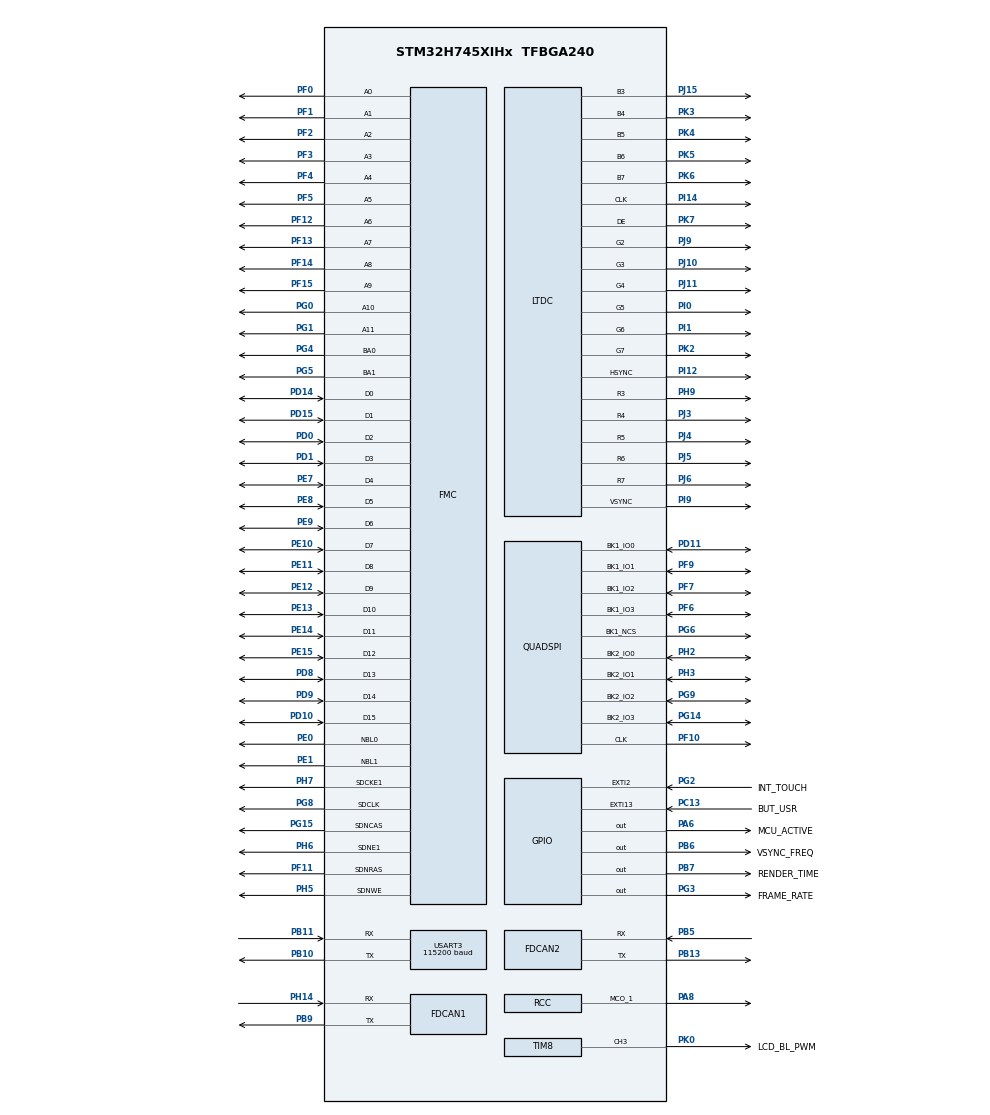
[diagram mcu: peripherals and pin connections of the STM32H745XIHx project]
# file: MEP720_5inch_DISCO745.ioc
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CORTEX_M7.AccessPermission-Cortex_Memory_Protection_Unit_Region0_Settings=MPU_REGION_FULL_ACCESS
CORTEX_M7.AccessPermission-Cortex_Memory_Protection_Unit_Region1_Settings=MPU_REGION_FULL_ACCESS
CORTEX_M7.AccessPermission-Cortex_Memory_Protection_Unit_Region2_Settings=MPU_REGION_FULL_ACCESS
CORTEX_M7.BaseAddress-Cortex_Memory_Protection_Unit_Region0_Settings=0x24000000
CORTEX_M7.BaseAddress-Cortex_Memory_Protection_Unit_Region1_Settings=0xD0000000
CORTEX_M7.BaseAddress-Cortex_Memory_Protection_Unit_Region2_Settings=0x90000000
CORTEX_M7.CPU_DCache=Enabled
CORTEX_M7.CPU_ICache=Enabled
CORTEX_M7.DisableExec-Cortex_Memory_Protection_Unit_Region0_Settings=MPU_INSTRUCTION_ACCESS_DISABLE
CORTEX_M7.DisableExec-Cortex_Memory_Protection_Unit_Region1_Settings=MPU_INSTRUCTION_ACCESS_ENABLE
CORTEX_M7.DisableExec-Cortex_Memory_Protection_Unit_Region2_Settings=MPU_INSTRUCTION_ACCESS_DISABLE
CORTEX_M7.Enable-Cortex_Memory_Protection_Unit_Region0_Settings=MPU_REGION_ENABLE
CORTEX_M7.Enable-Cortex_Memory_Protection_Unit_Region1_Settings=MPU_REGION_ENABLE
CORTEX_M7.Enable-Cortex_Memory_Protection_Unit_Region2_Settings=MPU_REGION_ENABLE
CORTEX_M7.Enable-Cortex_Memory_Protection_Unit_Region3_Settings=__NULL
CORTEX_M7.Enable-Cortex_Memory_Protection_Unit_Region4_Settings=__NULL
CORTEX_M7.IsBufferable-Cortex_Memory_Protection_Unit_Region0_Settings=MPU_ACCESS_BUFFERABLE
CORTEX_M7.IsBufferable-Cortex_Memory_Protection_Unit_Region1_Settings=MPU_ACCESS_NOT_BUFFERABLE
CORTEX_M7.IsBufferable-Cortex_Memory_Protection_Unit_Region2_Settings=MPU_ACCESS_BUFFERABLE
CORTEX_M7.IsCacheable-Cortex_Memory_Protection_Unit_Region0_Settings=MPU_ACCESS_CACHEABLE
CORTEX_M7.IsCacheable-Cortex_Memory_Protection_Unit_Region1_Settings=MPU_ACCESS_CACHEABLE
CORTEX_M7.IsCacheable-Cortex_Memory_Protection_Unit_Region2_Settings=MPU_ACCESS_CACHEABLE
CORTEX_M7.IsShareable-Cortex_Memory_Protection_Unit_Region1_Settings=MPU_ACCESS_NOT_SHAREABLE
CORTEX_M7.MPU_Control=MPU_PRIVILEGED_DEFAULT
CORTEX_M7.Size-Cortex_Memory_Protection_Unit_Region0_Settings=MPU_REGION_SIZE_512KB
CORTEX_M7.Size-Cortex_Memory_Protection_Unit_Region1_Settings=MPU_REGION_SIZE_8MB
CORTEX_M7.Size-Cortex_Memory_Protection_Unit_Region2_Settings=MPU_REGION_SIZE_128MB
CORTEX_M7.SubRegionDisable-Cortex_Memory_Protection_Unit_Region0_Settings=0x87
CortexM4.IPs=CORTEX_M4\:I,DEBUG,FATFS_M4\:I,FREERTOS_M4\:I,IWDG2\:I,OPENAMP_M4\:I,PDM2PCM_M4\:I,PWR,RCC,RESMGR_UTILITY,SYS_M4\:I,USB_DEVICE_M4\:I,USB_HOST_M4\:I,VREFBUF,WWDG2\:I,DMA,BDMA,MDMA,NVIC2\:I,GPIO,LPTIM3\:I
CortexM7.IPs=CORTEX_M7\:I,DEBUG\:I,FATFS_M7\:I,FREERTOS_M7\:I,IWDG1\:I,OPENAMP_M7\:I,PDM2PCM_M7\:I,PWR\:I,RCC\:I,RESMGR_UTILITY\:I,SYS\:I,USB_DEVICE_M7\:I,USB_HOST_M7\:I,VREFBUF\:I,WWDG1\:I,DMA\:I,BDMA\:I,MDMA\:I,NVIC1\:I,TIM6\:I,CRC\:I,LTDC\:I,DMA2D\:I,FMC\:I,QUADSPI\:I,GPIO\:I,JPEG\:I,FDCAN1\:I,FDCAN2\:I,USART3\:I,MEMORYMAP\:I,TIM8\:I,RTC\:I
CortexM7.Pins=PB6,PB7,PC13,PG3,PG2,PA6
DMA2D.ColorMode=DMA2D_OUTPUT_RGB565
DMA2D.Mode=DMA2D_R2M
FDCAN1.CalculateBaudRateNominal=1666666
FDCAN1.CalculateTimeBitNominal=600
FDCAN1.CalculateTimeQuantumNominal=200.0
FDCAN2.CalculateBaudRateNominal=1666666
FDCAN2.CalculateTimeBitNominal=600
FDCAN2.CalculateTimeQuantumNominal=200.0
FMC.CASLatency2=FMC_SDRAM_CAS_LATENCY_2
FMC.ExitSelfRefreshDelay2=6
FMC.LoadToActiveDelay2=2
FMC.RCDDelay2=2
FMC.RPDelay1=2
FMC.RPDelay2=2
FMC.ReadBurst2=FMC_SDRAM_RBURST_ENABLE
FMC.RowCycleDelay1=6
FMC.RowCycleDelay2=6
FMC.SDClockPeriod2=FMC_SDRAM_CLOCK_PERIOD_2
FMC.SelfRefreshTime2=4
FMC.WriteRecoveryTime2=2
FREERTOS_M7.Tasks01=defaultTask,8,1024,StartDefaultTask,Default,NULL,Static,defaultTaskBuffer,defaultTaskControlBlock
FREERTOS_M7.configGENERATE_RUN_TIME_STATS=1
FREERTOS_M7.configIDLE_SHOULD_YIELD=0
FREERTOS_M7.configMINIMAL_STACK_SIZE=512
FREERTOS_M7.configRECORD_STACK_HIGH_ADDRESS=1
FREERTOS_M7.configTIMER_TASK_PRIORITY=50
FREERTOS_M7.configTOTAL_HEAP_SIZE=65535
FREERTOS_M7.configUSE_NEWLIB_REENTRANT=1
FREERTOS_M7.configUSE_STATS_FORMATTING_FUNCTIONS=1
JPEG.JPEG_RGB_FORMAT=JPEG_RGB565
JPEG.USE_JPEG_ENCODER=0
LTDC.ActiveH=480
LTDC.ActiveW=800
LTDC.Alpha0_L0=0
LTDC.Alpha_L0=255
LTDC.BlendingFactor1_L0=LTDC_BLENDING_FACTOR1_CA
LTDC.BlendingFactor2_L0=LTDC_BLENDING_FACTOR2_CA
LTDC.FBStartAdress_L0=ltdc_buffer_addr()
LTDC.HBP=8
LTDC.HFP=8
LTDC.HSync=4
LTDC.ImageHeight_L0=480
LTDC.ImageWidth_L0=800
LTDC.Layers=0
LTDC.PixelFormat_L0=LTDC_PIXEL_FORMAT_RGB565
LTDC.VBP=8
LTDC.VFP=8
LTDC.VSync=4
LTDC.WindowX1_L0=800
LTDC.WindowY1_L0=480
Mcu.Family=STM32H7
Mcu.Name=STM32H745XIHx
Mcu.Package=TFBGA240
Mdma.MDMA_Channel6.JPEG_OUTFIFO_TH.0.BlockCount=0
Mdma.MDMA_Channel6.JPEG_OUTFIFO_TH.0.BlockDataLength=0
Mdma.MDMA_Channel6.JPEG_OUTFIFO_TH.0.BufferTransferLength=32
Mdma.MDMA_Channel6.JPEG_OUTFIFO_TH.0.CircularMode=MDMA_LINEAR_LIST
Mdma.MDMA_Channel6.JPEG_OUTFIFO_TH.0.DataAlignment=MDMA_DATAALIGN_PACKENABLE
Mdma.MDMA_Channel6.JPEG_OUTFIFO_TH.0.DestBlockAddressOffset=0
Mdma.MDMA_Channel6.JPEG_OUTFIFO_TH.0.DestBurst=MDMA_DEST_BURST_32BEATS
Mdma.MDMA_Channel6.JPEG_OUTFIFO_TH.0.DestDataSize=MDMA_DEST_DATASIZE_BYTE
Mdma.MDMA_Channel6.JPEG_OUTFIFO_TH.0.DestinationInc=MDMA_DEST_INC_BYTE
Mdma.MDMA_Channel6.JPEG_OUTFIFO_TH.0.DstAddress=0
Mdma.MDMA_Channel6.JPEG_OUTFIFO_TH.0.Endianness=MDMA_LITTLE_ENDIANNESS_PRESERVE
Mdma.MDMA_Channel6.JPEG_OUTFIFO_TH.0.Instance=MDMA_Channel6
Mdma.MDMA_Channel6.JPEG_OUTFIFO_TH.0.MaskAddress=0
Mdma.MDMA_Channel6.JPEG_OUTFIFO_TH.0.MaskData=0
Mdma.MDMA_Channel6.JPEG_OUTFIFO_TH.0.Priority=MDMA_PRIORITY_VERY_HIGH
Mdma.MDMA_Channel6.JPEG_OUTFIFO_TH.0.Rank=First
Mdma.MDMA_Channel6.JPEG_OUTFIFO_TH.0.SourceBlockAddressOffset=0
Mdma.MDMA_Channel6.JPEG_OUTFIFO_TH.0.SourceBurst=MDMA_SOURCE_BURST_32BEATS
Mdma.MDMA_Channel6.JPEG_OUTFIFO_TH.0.SourceDataSize=MDMA_SRC_DATASIZE_WORD
Mdma.MDMA_Channel6.JPEG_OUTFIFO_TH.0.SourceInc=MDMA_SRC_INC_DISABLE
Mdma.MDMA_Channel6.JPEG_OUTFIFO_TH.0.SrcAddress=0
Mdma.MDMA_Channel6.JPEG_OUTFIFO_TH.0.TransferTriggerMode=MDMA_BUFFER_TRANSFER
Mdma.MDMA_Channel6.Request0=JPEG_OUTFIFO_TH
Mdma.MDMA_Channel6.RequestsNb=1
Mdma.MDMA_Channel7.JPEG_INFIFO_TH.0.BlockCount=0
Mdma.MDMA_Channel7.JPEG_INFIFO_TH.0.BlockDataLength=0
Mdma.MDMA_Channel7.JPEG_INFIFO_TH.0.BufferTransferLength=32
Mdma.MDMA_Channel7.JPEG_INFIFO_TH.0.CircularMode=MDMA_LINEAR_LIST
Mdma.MDMA_Channel7.JPEG_INFIFO_TH.0.DataAlignment=MDMA_DATAALIGN_PACKENABLE
Mdma.MDMA_Channel7.JPEG_INFIFO_TH.0.DestBlockAddressOffset=0
Mdma.MDMA_Channel7.JPEG_INFIFO_TH.0.DestBurst=MDMA_DEST_BURST_16BEATS
Mdma.MDMA_Channel7.JPEG_INFIFO_TH.0.DestDataSize=MDMA_DEST_DATASIZE_WORD
Mdma.MDMA_Channel7.JPEG_INFIFO_TH.0.DestinationInc=MDMA_DEST_INC_DISABLE
Mdma.MDMA_Channel7.JPEG_INFIFO_TH.0.DstAddress=0
Mdma.MDMA_Channel7.JPEG_INFIFO_TH.0.Endianness=MDMA_LITTLE_ENDIANNESS_PRESERVE
Mdma.MDMA_Channel7.JPEG_INFIFO_TH.0.Instance=MDMA_Channel7
Mdma.MDMA_Channel7.JPEG_INFIFO_TH.0.MaskAddress=0
Mdma.MDMA_Channel7.JPEG_INFIFO_TH.0.MaskData=0
Mdma.MDMA_Channel7.JPEG_INFIFO_TH.0.Priority=MDMA_PRIORITY_HIGH
Mdma.MDMA_Channel7.JPEG_INFIFO_TH.0.Rank=First
Mdma.MDMA_Channel7.JPEG_INFIFO_TH.0.SourceBlockAddressOffset=0
Mdma.MDMA_Channel7.JPEG_INFIFO_TH.0.SourceBurst=MDMA_SOURCE_BURST_32BEATS
Mdma.MDMA_Channel7.JPEG_INFIFO_TH.0.SourceDataSize=MDMA_SRC_DATASIZE_BYTE
Mdma.MDMA_Channel7.JPEG_INFIFO_TH.0.SourceInc=MDMA_SRC_INC_BYTE
Mdma.MDMA_Channel7.JPEG_INFIFO_TH.0.SrcAddress=0
Mdma.MDMA_Channel7.JPEG_INFIFO_TH.0.TransferTriggerMode=MDMA_BUFFER_TRANSFER
Mdma.MDMA_Channel7.Request0=JPEG_INFIFO_TH
Mdma.MDMA_Channel7.RequestsNb=1
Mdma.RequestSet0=MDMA_Channel7
Mdma.RequestSet1=MDMA_Channel6
Mdma.RequestSetsNb=2
NVIC1.DMA2D_IRQn=true\:5\:0\:false\:false\:true\:true\:true\:true\:true
NVIC1.EXTI15_10_IRQn=true\:5\:0\:false\:false\:true\:true\:true\:true\:true
NVIC1.EXTI2_IRQn=true\:5\:0\:false\:false\:true\:true\:true\:true\:true
NVIC1.FDCAN1_IT0_IRQn=true\:5\:0\:false\:false\:true\:true\:true\:true\:true
NVIC1.FDCAN2_IT0_IRQn=true\:5\:0\:false\:false\:true\:true\:true\:true\:true
NVIC1.JPEG_IRQn=true\:5\:0\:true\:false\:true\:true\:true\:true\:true
NVIC1.LTDC_IRQn=true\:5\:0\:false\:false\:true\:true\:true\:true\:true
NVIC1.MDMA_IRQn=true\:5\:0\:true\:false\:true\:true\:false\:true\:true
NVIC1.PriorityGroup=NVIC_PRIORITYGROUP_4
NVIC1.QUADSPI_IRQn=true\:5\:0\:false\:false\:true\:true\:true\:true\:true
NVIC1.TIM6_DAC_IRQn=true\:15\:0\:true\:false\:true\:false\:false\:true\:true
NVIC1.TimeBase=TIM6_DAC_IRQn
NVIC1.TimeBaseIP=TIM6
NVIC2.PriorityGroup=NVIC_PRIORITYGROUP_4
PA6.GPIO_Label=MCU_ACTIVE
PA6.GPIO_Speed=GPIO_SPEED_FREQ_VERY_HIGH
PA6.PinAttribute=CortexM7
PA6.Signal=GPIO_Output
PA8.Mode=Clock-out-1
PA8.PinAttribute=Free
PA8.Signal=RCC_MCO_1
PB10.Mode=Asynchronous
PB10.PinAttribute=CortexM7
PB10.Signal=USART3_TX
PB11.GPIO_PuPd=GPIO_PULLUP
PB11.Mode=Asynchronous
PB11.PinAttribute=CortexM7
PB11.Signal=USART3_RX
PB13.Mode=FDCAN_Activate
PB13.PinAttribute=CortexM7
PB13.Signal=FDCAN2_TX
PB5.Mode=FDCAN_Activate
PB5.PinAttribute=CortexM7
PB5.Signal=FDCAN2_RX
PB6.GPIO_Label=VSYNC_FREQ
PB6.GPIO_Speed=GPIO_SPEED_FREQ_VERY_HIGH
PB6.PinAttribute=CortexM7
PB6.Signal=GPIO_Output
PB7.GPIO_FM7=__NULL
PB7.GPIO_Label=RENDER_TIME
PB7.GPIO_Speed=GPIO_SPEED_FREQ_VERY_HIGH
PB7.PinAttribute=CortexM7
PB7.Signal=GPIO_Output
PB9.Mode=FDCAN_Activate
PB9.PinAttribute=CortexM7
PB9.Signal=FDCAN1_TX
PC13.GPIO_Label=BUT_USR
PC13.GPIO_ModeDefaultEXTI=GPIO_MODE_IT_RISING
PC13.GPIO_PuPd=GPIO_NOPULL
PC13.PinAttribute=CortexM7
PC13.Signal=GPXTI13
PC14-OSC32_IN\ (OSC32_IN).Mode=LSE-External-Oscillator
PC14-OSC32_IN\ (OSC32_IN).PinAttribute=Free
PC14-OSC32_IN\ (OSC32_IN).Signal=RCC_OSC32_IN
PC15-OSC32_OUT\ (OSC32_OUT).Mode=LSE-External-Oscillator
PC15-OSC32_OUT\ (OSC32_OUT).PinAttribute=Free
PC15-OSC32_OUT\ (OSC32_OUT).Signal=RCC_OSC32_OUT
PD0.PinAttribute=CortexM7
PD0.Signal=FMC_D2_DA2
PD1.PinAttribute=CortexM7
PD1.Signal=FMC_D3_DA3
PD10.PinAttribute=CortexM7
PD10.Signal=FMC_D15_DA15
PD11.GPIO_Speed=GPIO_SPEED_FREQ_VERY_HIGH
PD11.Mode=Dual_Bank
PD11.PinAttribute=CortexM7
PD11.Signal=QUADSPI_BK1_IO0
PD14.PinAttribute=CortexM7
PD14.Signal=FMC_D0_DA0
PD15.PinAttribute=CortexM7
PD15.Signal=FMC_D1_DA1
PD8.PinAttribute=CortexM7
PD8.Signal=FMC_D13_DA13
PD9.PinAttribute=CortexM7
PD9.Signal=FMC_D14_DA14
PE0.PinAttribute=CortexM7
PE0.Signal=FMC_NBL0
PE1.PinAttribute=CortexM7
PE1.Signal=FMC_NBL1
PE10.PinAttribute=CortexM7
PE10.Signal=FMC_D7_DA7
PE11.PinAttribute=CortexM7
PE11.Signal=FMC_D8_DA8
PE12.PinAttribute=CortexM7
PE12.Signal=FMC_D9_DA9
PE13.PinAttribute=CortexM7
PE13.Signal=FMC_D10_DA10
PE14.PinAttribute=CortexM7
PE14.Signal=FMC_D11_DA11
PE15.PinAttribute=CortexM7
PE15.Signal=FMC_D12_DA12
PE7.PinAttribute=CortexM7
PE7.Signal=FMC_D4_DA4
PE8.PinAttribute=CortexM7
PE8.Signal=FMC_D5_DA5
PE9.PinAttribute=CortexM7
PE9.Signal=FMC_D6_DA6
PF0.PinAttribute=CortexM7
PF0.Signal=FMC_A0
PF1.PinAttribute=CortexM7
PF1.Signal=FMC_A1
PF10.GPIO_Speed=GPIO_SPEED_FREQ_VERY_HIGH
PF10.Mode=Dual_Bank
PF10.PinAttribute=CortexM7
PF10.Signal=QUADSPI_CLK
PF11.PinAttribute=CortexM7
PF11.Signal=FMC_SDNRAS
PF12.PinAttribute=CortexM7
PF12.Signal=FMC_A6
PF13.PinAttribute=CortexM7
PF13.Signal=FMC_A7
PF14.PinAttribute=CortexM7
PF14.Signal=FMC_A8
PF15.PinAttribute=CortexM7
PF15.Signal=FMC_A9
PF2.PinAttribute=CortexM7
PF2.Signal=FMC_A2
PF3.PinAttribute=CortexM7
PF3.Signal=FMC_A3
PF4.PinAttribute=CortexM7
PF4.Signal=FMC_A4
PF5.PinAttribute=CortexM7
PF5.Signal=FMC_A5
PF6.GPIO_Speed=GPIO_SPEED_FREQ_VERY_HIGH
PF6.Mode=Dual_Bank
PF6.PinAttribute=CortexM7
PF6.Signal=QUADSPI_BK1_IO3
PF7.GPIO_Speed=GPIO_SPEED_FREQ_VERY_HIGH
PF7.Mode=Dual_Bank
PF7.PinAttribute=CortexM7
PF7.Signal=QUADSPI_BK1_IO2
PF9.GPIO_Speed=GPIO_SPEED_FREQ_VERY_HIGH
PF9.Mode=Dual_Bank
PF9.PinAttribute=CortexM7
PF9.Signal=QUADSPI_BK1_IO1
PG0.PinAttribute=CortexM7
PG0.Signal=FMC_A10
PG1.PinAttribute=CortexM7
PG1.Signal=FMC_A11
PG14.GPIO_Speed=GPIO_SPEED_FREQ_VERY_HIGH
PG14.Mode=Dual_Bank
PG14.PinAttribute=CortexM7
PG14.Signal=QUADSPI_BK2_IO3
PG15.PinAttribute=CortexM7
PG15.Signal=FMC_SDNCAS
PG2.GPIO_Label=INT_TOUCH
PG2.GPIO_ModeDefaultEXTI=GPIO_MODE_IT_FALLING
PG2.GPIO_PuPd=GPIO_PULLUP
PG2.PinAttribute=CortexM7
PG2.Signal=GPXTI2
PG3.GPIO_Label=FRAME_RATE
PG3.GPIO_Speed=GPIO_SPEED_FREQ_VERY_HIGH
PG3.PinAttribute=CortexM7
PG3.Signal=GPIO_Output
PG4.PinAttribute=CortexM7
PG4.Signal=FMC_A14_BA0
PG5.PinAttribute=CortexM7
PG5.Signal=FMC_A15_BA1
PG6.GPIO_PuPd=GPIO_PULLUP
PG6.GPIO_Speed=GPIO_SPEED_FREQ_VERY_HIGH
PG6.Mode=Enable Chip Select 1 for both banks
PG6.PinAttribute=CortexM7
PG6.Signal=QUADSPI_BK1_NCS
PG8.PinAttribute=CortexM7
PG8.Signal=FMC_SDCLK
PG9.GPIO_Speed=GPIO_SPEED_FREQ_VERY_HIGH
PG9.Mode=Dual_Bank
PG9.PinAttribute=CortexM7
PG9.Signal=QUADSPI_BK2_IO2
PH0-OSC_IN\ (PH0).Mode=HSE-External-Oscillator
PH0-OSC_IN\ (PH0).PinAttribute=Free
PH0-OSC_IN\ (PH0).Signal=RCC_OSC_IN
PH1-OSC_OUT\ (PH1).Mode=HSE-External-Oscillator
PH1-OSC_OUT\ (PH1).PinAttribute=Free
PH1-OSC_OUT\ (PH1).Signal=RCC_OSC_OUT
PH14.Mode=FDCAN_Activate
PH14.PinAttribute=CortexM7
PH14.Signal=FDCAN1_RX
PH2.GPIO_Speed=GPIO_SPEED_FREQ_VERY_HIGH
PH2.Mode=Dual_Bank
PH2.PinAttribute=CortexM7
PH2.Signal=QUADSPI_BK2_IO0
PH3.GPIO_Speed=GPIO_SPEED_FREQ_VERY_HIGH
PH3.Mode=Dual_Bank
PH3.PinAttribute=CortexM7
PH3.Signal=QUADSPI_BK2_IO1
PH5.PinAttribute=CortexM7
PH5.Signal=FMC_SDNWE
PH6.Mode=SdramChipSelect2_2
PH6.PinAttribute=CortexM7
PH6.Signal=FMC_SDNE1
PH7.Mode=SdramChipSelect2_2
PH7.PinAttribute=CortexM7
PH7.Signal=FMC_SDCKE1
PH9.GPIO_Speed=GPIO_SPEED_FREQ_HIGH
PH9.Mode=RGB565
PH9.PinAttribute=CortexM7
PH9.Signal=LTDC_R3
PI0.GPIO_Speed=GPIO_SPEED_FREQ_HIGH
PI0.Mode=RGB565
PI0.PinAttribute=CortexM7
PI0.Signal=LTDC_G5
PI1.GPIO_Speed=GPIO_SPEED_FREQ_HIGH
PI1.Mode=RGB565
PI1.PinAttribute=CortexM7
PI1.Signal=LTDC_G6
PI12.GPIO_Speed=GPIO_SPEED_FREQ_HIGH
PI12.Mode=RGB565
PI12.PinAttribute=CortexM7
PI12.Signal=LTDC_HSYNC
PI14.GPIO_Speed=GPIO_SPEED_FREQ_HIGH
PI14.Mode=RGB565
PI14.PinAttribute=CortexM7
PI14.Signal=LTDC_CLK
PI15.GPIO_Speed=GPIO_SPEED_FREQ_HIGH
PI15.PinAttribute=CortexM7
PI15.Signal=LTDC_R0
PI9.GPIO_Speed=GPIO_SPEED_FREQ_HIGH
PI9.Mode=RGB565
PI9.PinAttribute=CortexM7
PI9.Signal=LTDC_VSYNC
PJ0.GPIO_Speed=GPIO_SPEED_FREQ_HIGH
PJ0.PinAttribute=CortexM7
PJ0.Signal=LTDC_R1
PJ1.GPIO_Speed=GPIO_SPEED_FREQ_HIGH
PJ1.PinAttribute=CortexM7
PJ1.Signal=LTDC_R2
PJ10.GPIO_Speed=GPIO_SPEED_FREQ_HIGH
PJ10.Mode=RGB565
PJ10.PinAttribute=CortexM7
PJ10.Signal=LTDC_G3
PJ11.GPIO_Speed=GPIO_SPEED_FREQ_HIGH
PJ11.Mode=RGB565
PJ11.PinAttribute=CortexM7
PJ11.Signal=LTDC_G4
PJ12.GPIO_Speed=GPIO_SPEED_FREQ_HIGH
PJ12.PinAttribute=CortexM7
PJ12.Signal=LTDC_B0
PJ13.GPIO_Speed=GPIO_SPEED_FREQ_HIGH
PJ13.PinAttribute=CortexM7
PJ13.Signal=LTDC_B1
PJ14.GPIO_Speed=GPIO_SPEED_FREQ_HIGH
PJ14.PinAttribute=CortexM7
PJ14.Signal=LTDC_B2
PJ15.GPIO_Speed=GPIO_SPEED_FREQ_HIGH
PJ15.Mode=RGB565
PJ15.PinAttribute=CortexM7
PJ15.Signal=LTDC_B3
PJ3.GPIO_Speed=GPIO_SPEED_FREQ_HIGH
PJ3.Mode=RGB565
PJ3.PinAttribute=CortexM7
PJ3.Signal=LTDC_R4
PJ4.GPIO_Speed=GPIO_SPEED_FREQ_HIGH
PJ4.Mode=RGB565
PJ4.PinAttribute=CortexM7
PJ4.Signal=LTDC_R5
PJ5.GPIO_Speed=GPIO_SPEED_FREQ_HIGH
PJ5.Mode=RGB565
PJ5.PinAttribute=CortexM7
PJ5.Signal=LTDC_R6
PJ6.GPIO_Speed=GPIO_SPEED_FREQ_HIGH
PJ6.Mode=RGB565
PJ6.PinAttribute=CortexM7
PJ6.Signal=LTDC_R7
PJ7.GPIO_Speed=GPIO_SPEED_FREQ_HIGH
PJ7.PinAttribute=CortexM7
PJ7.Signal=LTDC_G0
PJ8.GPIO_Speed=GPIO_SPEED_FREQ_HIGH
PJ8.PinAttribute=CortexM7
PJ8.Signal=LTDC_G1
PJ9.GPIO_Speed=GPIO_SPEED_FREQ_HIGH
PJ9.Mode=RGB565
PJ9.PinAttribute=CortexM7
PJ9.Signal=LTDC_G2
PK0.GPIO_Label=LCD_BL_PWM
PK0.GPIO_Speed=GPIO_SPEED_FREQ_MEDIUM
PK0.PinAttribute=CortexM7
PK0.Signal=S_TIM8_CH3
PK2.GPIO_Speed=GPIO_SPEED_FREQ_HIGH
PK2.Mode=RGB565
PK2.PinAttribute=CortexM7
PK2.Signal=LTDC_G7
PK3.GPIO_Speed=GPIO_SPEED_FREQ_HIGH
PK3.Mode=RGB565
PK3.PinAttribute=CortexM7
PK3.Signal=LTDC_B4
PK4.GPIO_Speed=GPIO_SPEED_FREQ_HIGH
PK4.Mode=RGB565
PK4.PinAttribute=CortexM7
PK4.Signal=LTDC_B5
PK5.GPIO_Speed=GPIO_SPEED_FREQ_HIGH
PK5.Mode=RGB565
PK5.PinAttribute=CortexM7
PK5.Signal=LTDC_B6
PK6.GPIO_Speed=GPIO_SPEED_FREQ_HIGH
PK6.Mode=RGB565
PK6.PinAttribute=CortexM7
PK6.Signal=LTDC_B7
PK7.GPIO_Speed=GPIO_SPEED_FREQ_HIGH
PK7.Mode=RGB565
PK7.PinAttribute=CortexM7
PK7.Signal=LTDC_DE
ProjectManager.HeapSize=M4-0x200,M7-0x1000
ProjectManager.StackSize=M4-0x400,M7-0x1000
ProjectManager.TargetToolchain=STM32CubeIDE
QUADSPI.ChipSelectHighTime=QSPI_CS_HIGH_TIME_3_CYCLE
QUADSPI.ClockPrescaler=1
QUADSPI.FlashSize=26
QUADSPI.SampleShifting=QSPI_SAMPLE_SHIFTING_HALFCYCLE
RCC.ADCFreq_Value=480000000
RCC.APB1Freq_Value=120000000
RCC.APB2Freq_Value=120000000
RCC.APB3Freq_Value=120000000
RCC.APB4Freq_Value=120000000
RCC.CortexFreq_Value=480000000
RCC.D1PPRE=RCC_APB3_DIV2
RCC.D2PPRE1=RCC_APB1_DIV2
RCC.D2PPRE2=RCC_APB2_DIV2
RCC.D3PPRE=RCC_APB4_DIV2
RCC.DIVM1=5
RCC.DIVM2=5
RCC.DIVM3=5
RCC.DIVN1=192
RCC.DIVN2=192
RCC.DIVN3=190
RCC.DIVQ1=6
RCC.DIVQ2=12
RCC.DIVQ3=10
RCC.DIVR2=5
RCC.DIVR3=41
RCC.FDCANCLockSelection=RCC_FDCANCLKSOURCE_PLL2
RCC.HCLKFreq_Value=240000000
RCC.HPRE=RCC_HCLK_DIV2
RCC.HSE_Timout=500
RCC.PLL2FRACN=0
RCC.PLL3FRACN=0
RCC.PLLFRACN=0
RCC.PLLSourceVirtual=RCC_PLLSOURCE_HSE
RCC.PWR_Regulator_Voltage_Scale=PWR_REGULATOR_VOLTAGE_SCALE0
RCC.QSPICLockSelection=RCC_QSPICLKSOURCE_PLL2
RCC.RCC_TIM_PRescaler_Selection=RCC_TIMPRES_DESACTIVATED
RCC.RTCClockSelection=RCC_RTCCLKSOURCE_LSE
RCC.SYSCLKFreq_VALUE=480000000
RCC.SYSCLKSource=RCC_SYSCLKSOURCE_PLLCLK
RCC.SupplySource=PWR_DIRECT_SMPS_SUPPLY
RCC.USBFreq_Value=160000000
SH.FMC_A0.0=FMC_A0,12b-sda2
SH.FMC_A1.0=FMC_A1,12b-sda2
SH.FMC_A10.0=FMC_A10,12b-sda2
SH.FMC_A11.0=FMC_A11,12b-sda2
SH.FMC_A14_BA0.0=FMC_BA0,FourSdramBanks2
SH.FMC_A15_BA1.0=FMC_BA1,FourSdramBanks2
SH.FMC_A2.0=FMC_A2,12b-sda2
SH.FMC_A3.0=FMC_A3,12b-sda2
SH.FMC_A4.0=FMC_A4,12b-sda2
SH.FMC_A5.0=FMC_A5,12b-sda2
SH.FMC_A6.0=FMC_A6,12b-sda2
SH.FMC_A7.0=FMC_A7,12b-sda2
SH.FMC_A8.0=FMC_A8,12b-sda2
SH.FMC_A9.0=FMC_A9,12b-sda2
SH.FMC_D0_DA0.0=FMC_D0,sd-16b-d2
SH.FMC_D10_DA10.0=FMC_D10,sd-16b-d2
SH.FMC_D11_DA11.0=FMC_D11,sd-16b-d2
SH.FMC_D12_DA12.0=FMC_D12,sd-16b-d2
SH.FMC_D13_DA13.0=FMC_D13,sd-16b-d2
SH.FMC_D14_DA14.0=FMC_D14,sd-16b-d2
SH.FMC_D15_DA15.0=FMC_D15,sd-16b-d2
SH.FMC_D1_DA1.0=FMC_D1,sd-16b-d2
SH.FMC_D2_DA2.0=FMC_D2,sd-16b-d2
SH.FMC_D3_DA3.0=FMC_D3,sd-16b-d2
SH.FMC_D4_DA4.0=FMC_D4,sd-16b-d2
SH.FMC_D5_DA5.0=FMC_D5,sd-16b-d2
SH.FMC_D6_DA6.0=FMC_D6,sd-16b-d2
SH.FMC_D7_DA7.0=FMC_D7,sd-16b-d2
SH.FMC_D8_DA8.0=FMC_D8,sd-16b-d2
SH.FMC_D9_DA9.0=FMC_D9,sd-16b-d2
SH.FMC_NBL0.0=FMC_NBL0,Sd2ByteEnable2
SH.FMC_NBL1.0=FMC_NBL1,Sd2ByteEnable2
SH.FMC_SDCLK.0=FMC_SDCLK,12b-sda2
SH.FMC_SDNCAS.0=FMC_SDNCAS,12b-sda2
SH.FMC_SDNRAS.0=FMC_SDNRAS,12b-sda2
SH.FMC_SDNWE.0=FMC_SDNWE,12b-sda2
SH.S_TIM8_CH3.0=TIM8_CH3,PWM Generation3 CH3
SYS.userName=SYS_M7
TIM8.Channel-PWM\ Generation3\ CH3=TIM_CHANNEL_3
TIM8.OC3Preload_PWM=ENABLE
TIM8.OCPolarity_3=TIM_OCPOLARITY_HIGH
TIM8.Period=50000
TIM8.Prescaler=5
TIM8.Pulse-PWM\ Generation3\ CH3=0
USART3.BaudRate=115200
USART3.ClockPrescaler=PRESCALER_DIV4
USART3.FIFOMode=FIFOMODE_ENABLE
USART3.Mode=MODE_TX_RX
USART3.VirtualMode-Asynchronous=VM_ASYNC
VP_CRC_VS_CRC.Mode=CRC_Activate
VP_DMA2D_VS_DMA2D.Mode=DMA2D_Activate
VP_FREERTOS_M7_VS_CMSIS_V2.Mode=CMSIS_V2
VP_JPEG_VS_JPEG.Mode=JPEG_Activate
VP_MEMORYMAP_VS_MEMORYMAP.Mode=CurAppReg
VP_RTC_VS_RTC_Activate.Mode=RTC_Enabled
VP_SYS_M4_VS_Systick.Mode=SysTick
VP_SYS_VS_tim6.Mode=TIM6
board=custom

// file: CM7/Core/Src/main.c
/* USER CODE BEGIN Header */
/**
  ******************************************************************************
  * @file           : main.c
  * @brief          : Main program body
  ******************************************************************************
  * @attention
  *
  * <h2><center>&copy; Copyright (c) 2021 STMicroelectronics.
  * All rights reserved.</center></h2>
  *
  * This software component is licensed by ST under Ultimate Liberty license
  * SLA0044, the "License"; You may not use this file except in compliance with
  * the License. You may obtain a copy of the License at:
  *                             www.st.com/SLA0044
  *
  ******************************************************************************
  */
/* USER CODE END Header */
#include "main.h"
#include "cmsis_os.h"

/* USER CODE BEGIN Includes */
#include "main_user.h"
#include "LVGL_port_screen.h"

__attribute__((section(".nvm_data"))) __attribute__((used)) volatile uint32_t nvm_config_data;

// MEP LTDC Buffer placed into SDRAM - MUSI BYT nastaven FrameBuffer LTDC (pak nize LTDC_Init pro kontrolu) v CubeMX na tuto fci !!! jinak kolize s Framebuf od LVGL !!!
static uint8_t ltdc_buffer[(MY_DISP_HOR_RES*MY_DISP_VER_RES)*2]__attribute__ (( section(".SDRAM_data"), used)) = {0}; // for RGB 565
uint32_t ltdc_buffer_addr(void)
{
  return (uint32_t)&ltdc_buffer[0];
}
/* USER CODE END Includes */

typedef StaticTask_t osStaticThreadDef_t;
/* USER CODE BEGIN PTD */
extern uint32_t *g_pfnVectors;

/* USER CODE END PTD */

/* USER CODE BEGIN PD */

#ifndef HSEM_ID_0
#define HSEM_ID_0 (0U) /* HW semaphore 0*/
#endif
/* USER CODE END PD */

/* USER CODE BEGIN PM */
const char _txt[] =  {"Test 1s \n" };
/* USER CODE END PM */

CRC_HandleTypeDef hcrc;

DMA2D_HandleTypeDef hdma2d;

FDCAN_HandleTypeDef hfdcan1;
FDCAN_HandleTypeDef hfdcan2;

JPEG_HandleTypeDef hjpeg;
MDMA_HandleTypeDef hmdma_jpeg_infifo_th;
MDMA_HandleTypeDef hmdma_jpeg_outfifo_th;

LTDC_HandleTypeDef hltdc;

QSPI_HandleTypeDef hqspi;

RTC_HandleTypeDef hrtc;

TIM_HandleTypeDef htim8;

UART_HandleTypeDef huart3;

SDRAM_HandleTypeDef hsdram2;

/* Definitions for defaultTask */
osThreadId_t defaultTaskHandle;
uint32_t defaultTaskBuffer[ 1024 ];
osStaticThreadDef_t defaultTaskControlBlock;
const osThreadAttr_t defaultTask_attributes = {
  .name = "defaultTask",
  .cb_mem = &defaultTaskControlBlock,
  .cb_size = sizeof(defaultTaskControlBlock),
  .stack_mem = &defaultTaskBuffer[0],
  .stack_size = sizeof(defaultTaskBuffer),
  .priority = (osPriority_t) osPriorityLow,
};
/* USER CODE BEGIN PV */
osThreadId_t lvglTickHandle;
const osThreadAttr_t lvglTick_attributes = {
  .name = "lvglTick",
  .priority = (osPriority_t) osPriorityAboveNormal,
  .stack_size = 4096
};

osThreadId_t lvglTimerHandle;
const osThreadAttr_t lvglTimer_attributes = {
  .name = "lvglTimer",
  .priority = (osPriority_t) osPriorityAboveNormal,
  .stack_size = 4096
};

/*
osThreadId_t taskMonitorHandle;
const osThreadAttr_t taskMonitor_attributes = {
  .name = "TaskMonitor",
  .priority = (osPriority_t) osPriorityLow, // Nižší priorita pro CPU profilování
  .stack_size = 4 * 1024
};
*/
/* USER CODE END PV */

void SystemClock_Config(void);
void PeriphCommonClock_Config(void);
static void MPU_Config(void);
static void MX_GPIO_Init(void);
static void MX_MDMA_Init(void);
static void MX_FMC_Init(void);
static void MX_TIM8_Init(void);
static void MX_LTDC_Init(void);
static void MX_CRC_Init(void);
static void MX_DMA2D_Init(void);
static void MX_JPEG_Init(void);
static void MX_QUADSPI_Init(void);
static void MX_FDCAN1_Init(void);
static void MX_FDCAN2_Init(void);
static void MX_USART3_UART_Init(void);
static void MX_RTC_Init(void);
void StartDefaultTask(void *argument);

/* USER CODE BEGIN PFP */
void LVGLTimer(void *argument);
void LVGLTick(void *argument);
void TaskMonitor(void *argument);
/* USER CODE END PFP */

/* USER CODE BEGIN 0 */

tMyLCD  myLCD;

//--------------------------------------------------------------------------------------
//  link printf to StlinkV3 USART serial port (USART3)
int _write(int file, char *ptr, int len) {
    HAL_UART_Transmit(&huart3, (uint8_t*)ptr, len, HAL_MAX_DELAY);
    return len;
}
//--------------------------------------------------------------------------------------
 // change LCD BL intesity via PWM 0 - 100%, Fpwm = 800hz (set via CubeMx - example Ftim = 240Mhz -> pre = 4, Counter period = 50000-1)
void LCD_SetBrightnessStart(TIM_HandleTypeDef *TIMx)
{
   if (HAL_TIM_PWM_Start(TIMx, TIM_CHANNEL_3) != HAL_OK)
	   Error_Handler();
}
//--------------------------------------------------------------------------------------
void LCD_SetBrightness(uint16_t percent)  //  0-499 -> 0-100%
{
    uint32_t max_value = LCD_BL_PWM_TIM.Instance->ARR;  // read actual Timer Counter-period value (set via CubeMx)

    if (percent > 500) percent = 500;
    uint32_t pwm_value = (uint32_t)percent * (max_value / 500u);
    LCD_BL_PWM_TIM.Instance->CCR3 = pwm_value;     // PK0 PWM set to channel 3
}
//--------------------------------------------------------------------------------------
//--------------------------------------------------------------------------------------

//--------------------------------------------------------------------------------------
PT_THREAD(LCD_SetBrightness_PT(struct pt *pt, uint16_t target_BL))  // change LCD BL PWM in non-blocking mode - need to call this PT periodicaly
{
   static uint16_t  out_BL=0;

   PT_BEGIN(pt);

   PT_WAIT_UNTIL(pt, myLCD.BL.enable == true);   // someone wants to set new backlight ?

   while (out_BL != target_BL)                  // Dokud není dosažen požadovaný jas
   {
	 if (out_BL < target_BL)		 out_BL++;                 // Pokud je třeba zvýšit jas
	 else if (out_BL > target_BL)    out_BL--;          // Pokud je třeba snížit jas

	 LCD_SetBrightness(out_BL);                 // Nastavení PWM
	 PT_YIELD(pt);                              // Vrátí řízení a čeká na další volání
   }

   myLCD.BL.enable = false;     // disable to set bl again, until someone wants to

   PT_END(pt);
}
//--------------------------------------------------------------------------------------

#define VT100_RESET   "\033[0m"
#define VT100_BOLD    "\033[1m"
#define VT100_GREEN   "\033[32m"
#define VT100_YELLOW  "\033[33m"
#define VT100_CLEAR   "\033[2J"
#define VT100_CURSOR_HOME "\033[H"

//*****************************************************************************//
void print_touch_pos_VT100(uint16_t x, uint16_t y) {
    printf(VT100_CLEAR); //
    printf(VT100_CURSOR_HOME); //

    printf(VT100_BOLD VT100_GREEN "Touch detected:\n" VT100_RESET);
    printf(VT100_YELLOW "X: %u\n", x);
    printf("Y: %u\n" VT100_RESET, y);
}

/* USER CODE END 0 */

int main(void)
{

  /* USER CODE BEGIN 1 */
  SCB->VTOR = (uint32_t)&g_pfnVectors;   // ONLY FOR BOOTLOADER, NOT USED HERE
  /* USER CODE END 1 */
/* USER CODE BEGIN Boot_Mode_Sequence_0 */
  int32_t timeout;
/* USER CODE END Boot_Mode_Sequence_0 */

  /* MPU Configuration--------------------------------------------------------*/
  MPU_Config();

  /* Enable the CPU Cache */

  /* Enable I-Cache---------------------------------------------------------*/
  SCB_EnableICache();

  /* Enable D-Cache---------------------------------------------------------*/
  SCB_EnableDCache();

/* USER CODE BEGIN Boot_Mode_Sequence_1 */
  /* Wait until CPU2 boots and enters in stop mode or timeout*/
//
//  timeout = 0xFFFF;
//  while((__HAL_RCC_GET_FLAG(RCC_FLAG_D2CKRDY) != RESET) && (timeout-- > 0));
//  if ( timeout < 0 )
//  {
//  Error_Handler();
//  }
/* USER CODE END Boot_Mode_Sequence_1 */
  /* MCU Configuration--------------------------------------------------------*/

  /* Reset of all peripherals, Initializes the Flash interface and the Systick. */
  HAL_Init();

  /* Configure the system clock */
  SystemClock_Config();

  /* Configure the peripherals common clocks */
  PeriphCommonClock_Config();
/* USER CODE BEGIN Boot_Mode_Sequence_2 */
/* When system initialization is finished, Cortex-M7 will release Cortex-M4 by means of
HSEM notification */
/*HW semaphore Clock enable*/
__HAL_RCC_HSEM_CLK_ENABLE();
/*Take HSEM */
HAL_HSEM_FastTake(HSEM_ID_0);
/*Release HSEM in order to notify the CPU2(CM4)*/
HAL_HSEM_Release(HSEM_ID_0,0);
/* wait until CPU2 wakes up from stop mode */
timeout = 0xFFFF;
while((__HAL_RCC_GET_FLAG(RCC_FLAG_D2CKRDY) == RESET) && (timeout-- > 0));
if ( timeout < 0 )
{
Error_Handler();
}
/* USER CODE END Boot_Mode_Sequence_2 */

  /* Initialize all configured peripherals */
  MX_GPIO_Init();
  MX_MDMA_Init();
  MX_FMC_Init();
  MX_TIM8_Init();
  MX_LTDC_Init();
  MX_CRC_Init();
  MX_DMA2D_Init();
  MX_JPEG_Init();
  MX_QUADSPI_Init();
  MX_FDCAN1_Init();
  MX_FDCAN2_Init();
  MX_USART3_UART_Init();
  MX_RTC_Init();
  /* USER CODE BEGIN 2 */

  BSP_LED_Init(LED1);
  BSP_LED_Init(LED2);

  // MEP - RTC enable -
   __HAL_RCC_RTC_ENABLE();   // Povolení RTC
   __HAL_RCC_LSE_CONFIG(RCC_LSE_ON);  // Zapnutí externího oscilátoru (LSE) // bylo OFF MEP
   __HAL_RCC_BKPRAM_CLK_ENABLE();
   HAL_PWREx_EnableBkUpReg();
   HAL_PWR_EnableBkUpAccess();

  //BSP_LCD_SetBrightness(0,10);

  printf ("LVGL port for STM32H745-DISCO - Petr Mervart \n)");

  // MEP - start LCD BL PWM control of brightness
  LCD_SetBrightness(0);     // 0-100%   - Brightness will change to 100% via PT calling

  // init Protothread to set brightness (after) reset
  PT_INIT(&myLCD.BL.pt);
  myLCD.BL.enable 		= false; // BL not allowd now - after all tasks have been started - see default task
  myLCD.BL.target 		=  50;     // 0-499 -> 0-100%
  myLCD.BL.target_old 	=   0;
  myLCD.BL.dir			=   1;   // po startu zaciname zvysovanim jasu
  myLCD.UsrBut.pres_tmr =   0;

  /* initialize LVGL framework */
  lv_init();
  lvgl_display_init();
  lvgl_touchscreen_init();

  if (RTC->BKP0R == 10)    // po stisku tlacitka aslespon 2s se nastavi na 1 a po restartu se spusti demo (po power off bezi
     lv_demo_widgets();
  else
     ui_init();        // MEP vlastni UI ve SquareLine Studio
   /* lvgl demo */
   //lv_demo_widgets();
   //lv_demo_keypad_encoder();
   //lv_demo_music();
   //lv_demo_benchmark();

  /* USER CODE END 2 */

  /* Init scheduler */
  osKernelInitialize();

  /* Create the thread(s) */
  /* creation of defaultTask */
  defaultTaskHandle = osThreadNew(StartDefaultTask, NULL, &defaultTask_attributes);

  /* USER CODE BEGIN RTOS_THREADS */
  /* add threads, ... */
   // MEP - Lvgl threads
  lvglTickHandle 		= osThreadNew(LVGLTick, NULL, &lvglTick_attributes);
  lvglTimerHandle 		= osThreadNew(LVGLTimer, NULL, &lvglTimer_attributes);
  //taskMonitorHandle 	= osThreadNew(TaskMonitor, NULL, &taskMonitor_attributes);

  /* USER CODE END RTOS_THREADS */

  /* Start scheduler */
  osKernelStart();

  /* We should never get here as control is now taken by the scheduler */

  /* Infinite loop */
  while (1)
  {

  }
}

void SystemClock_Config(void)
{
  RCC_OscInitTypeDef RCC_OscInitStruct = {0};
  RCC_ClkInitTypeDef RCC_ClkInitStruct = {0};

  /** Supply configuration update enable
  */
  HAL_PWREx_ConfigSupply(PWR_DIRECT_SMPS_SUPPLY);

  /** Configure the main internal regulator output voltage
  */
  __HAL_PWR_VOLTAGESCALING_CONFIG(PWR_REGULATOR_VOLTAGE_SCALE0);

  while(!__HAL_PWR_GET_FLAG(PWR_FLAG_VOSRDY)) {}

  /** Configure LSE Drive Capability
  */
  HAL_PWR_EnableBkUpAccess();
  __HAL_RCC_LSEDRIVE_CONFIG(RCC_LSEDRIVE_LOW);

  /** Initializes the RCC Oscillators according to the specified parameters
  * in the RCC_OscInitTypeDef structure.
  */
  RCC_OscInitStruct.OscillatorType = RCC_OSCILLATORTYPE_HSI|RCC_OSCILLATORTYPE_HSE
                              |RCC_OSCILLATORTYPE_LSE;
  RCC_OscInitStruct.HSEState = RCC_HSE_ON;
  RCC_OscInitStruct.LSEState = RCC_LSE_ON;
  RCC_OscInitStruct.HSIState = RCC_HSI_DIV1;
  RCC_OscInitStruct.HSICalibrationValue = RCC_HSICALIBRATION_DEFAULT;
  RCC_OscInitStruct.PLL.PLLState = RCC_PLL_ON;
  RCC_OscInitStruct.PLL.PLLSource = RCC_PLLSOURCE_HSE;
  RCC_OscInitStruct.PLL.PLLM = 5;
  RCC_OscInitStruct.PLL.PLLN = 192;
  RCC_OscInitStruct.PLL.PLLP = 2;
  RCC_OscInitStruct.PLL.PLLQ = 6;
  RCC_OscInitStruct.PLL.PLLR = 2;
  RCC_OscInitStruct.PLL.PLLRGE = RCC_PLL1VCIRANGE_2;
  RCC_OscInitStruct.PLL.PLLVCOSEL = RCC_PLL1VCOWIDE;
  RCC_OscInitStruct.PLL.PLLFRACN = 0;
  if (HAL_RCC_OscConfig(&RCC_OscInitStruct) != HAL_OK)
  {
    Error_Handler();
  }

  /** Initializes the CPU, AHB and APB buses clocks
  */
  RCC_ClkInitStruct.ClockType = RCC_CLOCKTYPE_HCLK|RCC_CLOCKTYPE_SYSCLK
                              |RCC_CLOCKTYPE_PCLK1|RCC_CLOCKTYPE_PCLK2
                              |RCC_CLOCKTYPE_D3PCLK1|RCC_CLOCKTYPE_D1PCLK1;
  RCC_ClkInitStruct.SYSCLKSource = RCC_SYSCLKSOURCE_PLLCLK;
  RCC_ClkInitStruct.SYSCLKDivider = RCC_SYSCLK_DIV1;
  RCC_ClkInitStruct.AHBCLKDivider = RCC_HCLK_DIV2;
  RCC_ClkInitStruct.APB3CLKDivider = RCC_APB3_DIV2;
  RCC_ClkInitStruct.APB1CLKDivider = RCC_APB1_DIV2;
  RCC_ClkInitStruct.APB2CLKDivider = RCC_APB2_DIV2;
  RCC_ClkInitStruct.APB4CLKDivider = RCC_APB4_DIV2;

  if (HAL_RCC_ClockConfig(&RCC_ClkInitStruct, FLASH_LATENCY_4) != HAL_OK)
  {
    Error_Handler();
  }
  HAL_RCC_MCOConfig(RCC_MCO1, RCC_MCO1SOURCE_HSI, RCC_MCODIV_1);
}

void PeriphCommonClock_Config(void)
{
  RCC_PeriphCLKInitTypeDef PeriphClkInitStruct = {0};

  /** Initializes the peripherals clock
  */
  PeriphClkInitStruct.PeriphClockSelection = RCC_PERIPHCLK_QSPI|RCC_PERIPHCLK_FDCAN;
  PeriphClkInitStruct.PLL2.PLL2M = 5;
  PeriphClkInitStruct.PLL2.PLL2N = 192;
  PeriphClkInitStruct.PLL2.PLL2P = 2;
  PeriphClkInitStruct.PLL2.PLL2Q = 12;
  PeriphClkInitStruct.PLL2.PLL2R = 5;
  PeriphClkInitStruct.PLL2.PLL2RGE = RCC_PLL2VCIRANGE_2;
  PeriphClkInitStruct.PLL2.PLL2VCOSEL = RCC_PLL2VCOWIDE;
  PeriphClkInitStruct.PLL2.PLL2FRACN = 0;
  PeriphClkInitStruct.QspiClockSelection = RCC_QSPICLKSOURCE_PLL2;
  PeriphClkInitStruct.FdcanClockSelection = RCC_FDCANCLKSOURCE_PLL2;
  if (HAL_RCCEx_PeriphCLKConfig(&PeriphClkInitStruct) != HAL_OK)
  {
    Error_Handler();
  }
}

static void MX_CRC_Init(void)
{

  hcrc.Instance = CRC;
  hcrc.Init.DefaultPolynomialUse = DEFAULT_POLYNOMIAL_ENABLE;
  hcrc.Init.DefaultInitValueUse = DEFAULT_INIT_VALUE_ENABLE;
  hcrc.Init.InputDataInversionMode = CRC_INPUTDATA_INVERSION_NONE;
  hcrc.Init.OutputDataInversionMode = CRC_OUTPUTDATA_INVERSION_DISABLE;
  hcrc.InputDataFormat = CRC_INPUTDATA_FORMAT_BYTES;
  if (HAL_CRC_Init(&hcrc) != HAL_OK)
  {
    Error_Handler();
  }

}

static void MX_DMA2D_Init(void)
{

  hdma2d.Instance = DMA2D;
  hdma2d.Init.Mode = DMA2D_R2M;
  hdma2d.Init.ColorMode = DMA2D_OUTPUT_RGB565;
  hdma2d.Init.OutputOffset = 0;
  if (HAL_DMA2D_Init(&hdma2d) != HAL_OK)
  {
    Error_Handler();
  }

}

static void MX_FDCAN1_Init(void)
{

  hfdcan1.Instance = FDCAN1;
  hfdcan1.Init.FrameFormat = FDCAN_FRAME_CLASSIC;
  hfdcan1.Init.Mode = FDCAN_MODE_NORMAL;
  hfdcan1.Init.AutoRetransmission = DISABLE;
  hfdcan1.Init.TransmitPause = DISABLE;
  hfdcan1.Init.ProtocolException = DISABLE;
  hfdcan1.Init.NominalPrescaler = 16;
  hfdcan1.Init.NominalSyncJumpWidth = 1;
  hfdcan1.Init.NominalTimeSeg1 = 1;
  hfdcan1.Init.NominalTimeSeg2 = 1;
  hfdcan1.Init.DataPrescaler = 1;
  hfdcan1.Init.DataSyncJumpWidth = 1;
  hfdcan1.Init.DataTimeSeg1 = 1;
  hfdcan1.Init.DataTimeSeg2 = 1;
  hfdcan1.Init.MessageRAMOffset = 0;
  hfdcan1.Init.StdFiltersNbr = 0;
  hfdcan1.Init.ExtFiltersNbr = 0;
  hfdcan1.Init.RxFifo0ElmtsNbr = 0;
  hfdcan1.Init.RxFifo0ElmtSize = FDCAN_DATA_BYTES_8;
  hfdcan1.Init.RxFifo1ElmtsNbr = 0;
  hfdcan1.Init.RxFifo1ElmtSize = FDCAN_DATA_BYTES_8;
  hfdcan1.Init.RxBuffersNbr = 0;
  hfdcan1.Init.RxBufferSize = FDCAN_DATA_BYTES_8;
  hfdcan1.Init.TxEventsNbr = 0;
  hfdcan1.Init.TxBuffersNbr = 0;
  hfdcan1.Init.TxFifoQueueElmtsNbr = 0;
  hfdcan1.Init.TxFifoQueueMode = FDCAN_TX_FIFO_OPERATION;
  hfdcan1.Init.TxElmtSize = FDCAN_DATA_BYTES_8;
  if (HAL_FDCAN_Init(&hfdcan1) != HAL_OK)
  {
    Error_Handler();
  }

}

static void MX_FDCAN2_Init(void)
{

  hfdcan2.Instance = FDCAN2;
  hfdcan2.Init.FrameFormat = FDCAN_FRAME_CLASSIC;
  hfdcan2.Init.Mode = FDCAN_MODE_NORMAL;
  hfdcan2.Init.AutoRetransmission = DISABLE;
  hfdcan2.Init.TransmitPause = DISABLE;
  hfdcan2.Init.ProtocolException = DISABLE;
  hfdcan2.Init.NominalPrescaler = 16;
  hfdcan2.Init.NominalSyncJumpWidth = 1;
  hfdcan2.Init.NominalTimeSeg1 = 1;
  hfdcan2.Init.NominalTimeSeg2 = 1;
  hfdcan2.Init.DataPrescaler = 1;
  hfdcan2.Init.DataSyncJumpWidth = 1;
  hfdcan2.Init.DataTimeSeg1 = 1;
  hfdcan2.Init.DataTimeSeg2 = 1;
  hfdcan2.Init.MessageRAMOffset = 0;
  hfdcan2.Init.StdFiltersNbr = 0;
  hfdcan2.Init.ExtFiltersNbr = 0;
  hfdcan2.Init.RxFifo0ElmtsNbr = 0;
  hfdcan2.Init.RxFifo0ElmtSize = FDCAN_DATA_BYTES_8;
  hfdcan2.Init.RxFifo1ElmtsNbr = 0;
  hfdcan2.Init.RxFifo1ElmtSize = FDCAN_DATA_BYTES_8;
  hfdcan2.Init.RxBuffersNbr = 0;
  hfdcan2.Init.RxBufferSize = FDCAN_DATA_BYTES_8;
  hfdcan2.Init.TxEventsNbr = 0;
  hfdcan2.Init.TxBuffersNbr = 0;
  hfdcan2.Init.TxFifoQueueElmtsNbr = 0;
  hfdcan2.Init.TxFifoQueueMode = FDCAN_TX_FIFO_OPERATION;
  hfdcan2.Init.TxElmtSize = FDCAN_DATA_BYTES_8;
  if (HAL_FDCAN_Init(&hfdcan2) != HAL_OK)
  {
    Error_Handler();
  }

}

static void MX_JPEG_Init(void)
{

  hjpeg.Instance = JPEG;
  if (HAL_JPEG_Init(&hjpeg) != HAL_OK)
  {
    Error_Handler();
  }

}

static void MX_LTDC_Init(void)
{

  /* USER CODE BEGIN LTDC_Init 0 */
  initLtdcClocks();
  /* USER CODE END LTDC_Init 0 */

  LTDC_LayerCfgTypeDef pLayerCfg = {0};

  hltdc.Instance = LTDC;
  hltdc.Init.HSPolarity = LTDC_HSPOLARITY_AL;
  hltdc.Init.VSPolarity = LTDC_VSPOLARITY_AL;
  hltdc.Init.DEPolarity = LTDC_DEPOLARITY_AL;
  hltdc.Init.PCPolarity = LTDC_PCPOLARITY_IPC;
  hltdc.Init.HorizontalSync = 3;
  hltdc.Init.VerticalSync = 3;
  hltdc.Init.AccumulatedHBP = 11;
  hltdc.Init.AccumulatedVBP = 11;
  hltdc.Init.AccumulatedActiveW = 811;
  hltdc.Init.AccumulatedActiveH = 491;
  hltdc.Init.TotalWidth = 819;
  hltdc.Init.TotalHeigh = 499;
  hltdc.Init.Backcolor.Blue = 0;
  hltdc.Init.Backcolor.Green = 0;
  hltdc.Init.Backcolor.Red = 0;
  if (HAL_LTDC_Init(&hltdc) != HAL_OK)
  {
    Error_Handler();
  }
  pLayerCfg.WindowX0 = 0;
  pLayerCfg.WindowX1 = 800;
  pLayerCfg.WindowY0 = 0;
  pLayerCfg.WindowY1 = 480;
  pLayerCfg.PixelFormat = LTDC_PIXEL_FORMAT_RGB565;
  pLayerCfg.Alpha = 255;
  pLayerCfg.Alpha0 = 0;
  pLayerCfg.BlendingFactor1 = LTDC_BLENDING_FACTOR1_CA;
  pLayerCfg.BlendingFactor2 = LTDC_BLENDING_FACTOR2_CA;
  pLayerCfg.FBStartAdress = ltdc_buffer_addr();
  pLayerCfg.ImageWidth = 800;
  pLayerCfg.ImageHeight = 480;
  pLayerCfg.Backcolor.Blue = 0;
  pLayerCfg.Backcolor.Green = 0;
  pLayerCfg.Backcolor.Red = 0;
  if (HAL_LTDC_ConfigLayer(&hltdc, &pLayerCfg, 0) != HAL_OK)
  {
    Error_Handler();
  }

}

static void MX_QUADSPI_Init(void)
{

  /* QUADSPI parameter configuration*/
  hqspi.Instance = QUADSPI;
  hqspi.Init.ClockPrescaler = 1;
  hqspi.Init.FifoThreshold = 1;
  hqspi.Init.SampleShifting = QSPI_SAMPLE_SHIFTING_HALFCYCLE;
  hqspi.Init.FlashSize = 26;
  hqspi.Init.ChipSelectHighTime = QSPI_CS_HIGH_TIME_3_CYCLE;
  hqspi.Init.ClockMode = QSPI_CLOCK_MODE_0;
  hqspi.Init.DualFlash = QSPI_DUALFLASH_ENABLE;
  if (HAL_QSPI_Init(&hqspi) != HAL_OK)
  {
    Error_Handler();
  }
  /* USER CODE BEGIN QUADSPI_Init 2 */
  initBspQuadSpi(&Error_Handler);
  /* USER CODE END QUADSPI_Init 2 */

}

static void MX_RTC_Init(void)
{

  /** Initialize RTC Only
  */
  hrtc.Instance = RTC;
  hrtc.Init.HourFormat = RTC_HOURFORMAT_24;
  hrtc.Init.AsynchPrediv = 127;
  hrtc.Init.SynchPrediv = 255;
  hrtc.Init.OutPut = RTC_OUTPUT_DISABLE;
  hrtc.Init.OutPutPolarity = RTC_OUTPUT_POLARITY_HIGH;
  hrtc.Init.OutPutType = RTC_OUTPUT_TYPE_OPENDRAIN;
  hrtc.Init.OutPutRemap = RTC_OUTPUT_REMAP_NONE;
  if (HAL_RTC_Init(&hrtc) != HAL_OK)
  {
    Error_Handler();
  }

}

static void MX_TIM8_Init(void)
{

  TIM_MasterConfigTypeDef sMasterConfig = {0};
  TIM_OC_InitTypeDef sConfigOC = {0};
  TIM_BreakDeadTimeConfigTypeDef sBreakDeadTimeConfig = {0};

  /* USER CODE BEGIN TIM8_Init 1 */
  htim8.Instance->CCR3 = 0;            // MEP add - BL OFF
  /* USER CODE END TIM8_Init 1 */
  htim8.Instance = TIM8;
  htim8.Init.Prescaler = 5;
  htim8.Init.CounterMode = TIM_COUNTERMODE_UP;
  htim8.Init.Period = 50000;
  htim8.Init.ClockDivision = TIM_CLOCKDIVISION_DIV1;
  htim8.Init.RepetitionCounter = 0;
  htim8.Init.AutoReloadPreload = TIM_AUTORELOAD_PRELOAD_DISABLE;
  if (HAL_TIM_PWM_Init(&htim8) != HAL_OK)
  {
    Error_Handler();
  }
  sMasterConfig.MasterOutputTrigger = TIM_TRGO_RESET;
  sMasterConfig.MasterOutputTrigger2 = TIM_TRGO2_RESET;
  sMasterConfig.MasterSlaveMode = TIM_MASTERSLAVEMODE_DISABLE;
  if (HAL_TIMEx_MasterConfigSynchronization(&htim8, &sMasterConfig) != HAL_OK)
  {
    Error_Handler();
  }
  sConfigOC.OCMode = TIM_OCMODE_PWM1;
  sConfigOC.Pulse = 0;
  sConfigOC.OCPolarity = TIM_OCPOLARITY_HIGH;
  sConfigOC.OCNPolarity = TIM_OCNPOLARITY_HIGH;
  sConfigOC.OCFastMode = TIM_OCFAST_DISABLE;
  sConfigOC.OCIdleState = TIM_OCIDLESTATE_RESET;
  sConfigOC.OCNIdleState = TIM_OCNIDLESTATE_RESET;
  if (HAL_TIM_PWM_ConfigChannel(&htim8, &sConfigOC, TIM_CHANNEL_3) != HAL_OK)
  {
    Error_Handler();
  }
  sBreakDeadTimeConfig.OffStateRunMode = TIM_OSSR_DISABLE;
  sBreakDeadTimeConfig.OffStateIDLEMode = TIM_OSSI_DISABLE;
  sBreakDeadTimeConfig.LockLevel = TIM_LOCKLEVEL_OFF;
  sBreakDeadTimeConfig.DeadTime = 0;
  sBreakDeadTimeConfig.BreakState = TIM_BREAK_DISABLE;
  sBreakDeadTimeConfig.BreakPolarity = TIM_BREAKPOLARITY_HIGH;
  sBreakDeadTimeConfig.BreakFilter = 0;
  sBreakDeadTimeConfig.Break2State = TIM_BREAK2_DISABLE;
  sBreakDeadTimeConfig.Break2Polarity = TIM_BREAK2POLARITY_HIGH;
  sBreakDeadTimeConfig.Break2Filter = 0;
  sBreakDeadTimeConfig.AutomaticOutput = TIM_AUTOMATICOUTPUT_DISABLE;
  if (HAL_TIMEx_ConfigBreakDeadTime(&htim8, &sBreakDeadTimeConfig) != HAL_OK)
  {
    Error_Handler();
  }
  HAL_TIM_MspPostInit(&htim8);

}

static void MX_USART3_UART_Init(void)
{

  huart3.Instance = USART3;
  huart3.Init.BaudRate = 115200;
  huart3.Init.WordLength = UART_WORDLENGTH_8B;
  huart3.Init.StopBits = UART_STOPBITS_1;
  huart3.Init.Parity = UART_PARITY_NONE;
  huart3.Init.Mode = UART_MODE_TX_RX;
  huart3.Init.HwFlowCtl = UART_HWCONTROL_NONE;
  huart3.Init.OverSampling = UART_OVERSAMPLING_16;
  huart3.Init.OneBitSampling = UART_ONE_BIT_SAMPLE_DISABLE;
  huart3.Init.ClockPrescaler = UART_PRESCALER_DIV4;
  huart3.AdvancedInit.AdvFeatureInit = UART_ADVFEATURE_NO_INIT;
  if (HAL_UART_Init(&huart3) != HAL_OK)
  {
    Error_Handler();
  }
  if (HAL_UARTEx_SetTxFifoThreshold(&huart3, UART_TXFIFO_THRESHOLD_1_8) != HAL_OK)
  {
    Error_Handler();
  }
  if (HAL_UARTEx_SetRxFifoThreshold(&huart3, UART_RXFIFO_THRESHOLD_1_8) != HAL_OK)
  {
    Error_Handler();
  }
  if (HAL_UARTEx_EnableFifoMode(&huart3) != HAL_OK)
  {
    Error_Handler();
  }

}

/**
  * Enable MDMA controller clock
  */
static void MX_MDMA_Init(void)
{

  /* MDMA controller clock enable */
  __HAL_RCC_MDMA_CLK_ENABLE();
  /* Local variables */

  /* MDMA interrupt initialization */
  /* MDMA_IRQn interrupt configuration */
  HAL_NVIC_SetPriority(MDMA_IRQn, 5, 0);
  HAL_NVIC_EnableIRQ(MDMA_IRQn);

}

/* FMC initialization function */
void MX_FMC_Init(void)
{

  FMC_SDRAM_TimingTypeDef SdramTiming = {0};

  /** Perform the SDRAM2 memory initialization sequence
  */
  hsdram2.Instance = FMC_SDRAM_DEVICE;
  /* hsdram2.Init */
  hsdram2.Init.SDBank = FMC_SDRAM_BANK2;
  hsdram2.Init.ColumnBitsNumber = FMC_SDRAM_COLUMN_BITS_NUM_8;
  hsdram2.Init.RowBitsNumber = FMC_SDRAM_ROW_BITS_NUM_12;
  hsdram2.Init.MemoryDataWidth = FMC_SDRAM_MEM_BUS_WIDTH_16;
  hsdram2.Init.InternalBankNumber = FMC_SDRAM_INTERN_BANKS_NUM_4;
  hsdram2.Init.CASLatency = FMC_SDRAM_CAS_LATENCY_2;
  hsdram2.Init.WriteProtection = FMC_SDRAM_WRITE_PROTECTION_DISABLE;
  hsdram2.Init.SDClockPeriod = FMC_SDRAM_CLOCK_PERIOD_2;
  hsdram2.Init.ReadBurst = FMC_SDRAM_RBURST_ENABLE;
  hsdram2.Init.ReadPipeDelay = FMC_SDRAM_RPIPE_DELAY_0;
  /* SdramTiming */
  SdramTiming.LoadToActiveDelay = 2;
  SdramTiming.ExitSelfRefreshDelay = 6;
  SdramTiming.SelfRefreshTime = 4;
  SdramTiming.RowCycleDelay = 6;
  SdramTiming.WriteRecoveryTime = 2;
  SdramTiming.RPDelay = 2;
  SdramTiming.RCDDelay = 2;

  if (HAL_SDRAM_Init(&hsdram2, &SdramTiming) != HAL_OK)
  {
    Error_Handler( );
  }

  /* USER CODE BEGIN FMC_Init 2 */
  initBspSdRam(&Error_Handler);
  /* USER CODE END FMC_Init 2 */
}

static void MX_GPIO_Init(void)
{
  GPIO_InitTypeDef GPIO_InitStruct = {0};

  /* GPIO Ports Clock Enable */
  __HAL_RCC_GPIOB_CLK_ENABLE();
  __HAL_RCC_GPIOK_CLK_ENABLE();
  __HAL_RCC_GPIOG_CLK_ENABLE();
  __HAL_RCC_GPIOI_CLK_ENABLE();
  __HAL_RCC_GPIOE_CLK_ENABLE();
  __HAL_RCC_GPIOJ_CLK_ENABLE();
  __HAL_RCC_GPIOH_CLK_ENABLE();
  __HAL_RCC_GPIOD_CLK_ENABLE();
  __HAL_RCC_GPIOC_CLK_ENABLE();
  __HAL_RCC_GPIOF_CLK_ENABLE();
  __HAL_RCC_GPIOA_CLK_ENABLE();

  /*Configure GPIO pin Output Level */
  HAL_GPIO_WritePin(GPIOB, VSYNC_FREQ_Pin|RENDER_TIME_Pin, GPIO_PIN_RESET);

  /*Configure GPIO pin Output Level */
  HAL_GPIO_WritePin(FRAME_RATE_GPIO_Port, FRAME_RATE_Pin, GPIO_PIN_RESET);

  /*Configure GPIO pin Output Level */
  HAL_GPIO_WritePin(MCU_ACTIVE_GPIO_Port, MCU_ACTIVE_Pin, GPIO_PIN_RESET);

  /*Configure GPIO pins : VSYNC_FREQ_Pin RENDER_TIME_Pin */
  GPIO_InitStruct.Pin = VSYNC_FREQ_Pin|RENDER_TIME_Pin;
  GPIO_InitStruct.Mode = GPIO_MODE_OUTPUT_PP;
  GPIO_InitStruct.Pull = GPIO_NOPULL;
  GPIO_InitStruct.Speed = GPIO_SPEED_FREQ_VERY_HIGH;
  HAL_GPIO_Init(GPIOB, &GPIO_InitStruct);

  /*Configure GPIO pin : BUT_USR_Pin */
  GPIO_InitStruct.Pin = BUT_USR_Pin;
  GPIO_InitStruct.Mode = GPIO_MODE_IT_RISING;
  GPIO_InitStruct.Pull = GPIO_NOPULL;
  HAL_GPIO_Init(BUT_USR_GPIO_Port, &GPIO_InitStruct);

  /*Configure GPIO pin : FRAME_RATE_Pin */
  GPIO_InitStruct.Pin = FRAME_RATE_Pin;
  GPIO_InitStruct.Mode = GPIO_MODE_OUTPUT_PP;
  GPIO_InitStruct.Pull = GPIO_NOPULL;
  GPIO_InitStruct.Speed = GPIO_SPEED_FREQ_VERY_HIGH;
  HAL_GPIO_Init(FRAME_RATE_GPIO_Port, &GPIO_InitStruct);

  /*Configure GPIO pin : INT_TOUCH_Pin */
  GPIO_InitStruct.Pin = INT_TOUCH_Pin;
  GPIO_InitStruct.Mode = GPIO_MODE_IT_FALLING;
  GPIO_InitStruct.Pull = GPIO_PULLUP;
  HAL_GPIO_Init(INT_TOUCH_GPIO_Port, &GPIO_InitStruct);

  /*Configure GPIO pin : MCU_ACTIVE_Pin */
  GPIO_InitStruct.Pin = MCU_ACTIVE_Pin;
  GPIO_InitStruct.Mode = GPIO_MODE_OUTPUT_PP;
  GPIO_InitStruct.Pull = GPIO_NOPULL;
  GPIO_InitStruct.Speed = GPIO_SPEED_FREQ_VERY_HIGH;
  HAL_GPIO_Init(MCU_ACTIVE_GPIO_Port, &GPIO_InitStruct);

  /* EXTI interrupt init*/
  HAL_NVIC_SetPriority(INT_TOUCH_EXTI_IRQn, 5, 0);
  HAL_NVIC_EnableIRQ(INT_TOUCH_EXTI_IRQn);

  HAL_NVIC_SetPriority(BUT_USR_EXTI_IRQn, 5, 0);
  HAL_NVIC_EnableIRQ(BUT_USR_EXTI_IRQn);

}

/* USER CODE BEGIN 4 */
/**********************************************************************************/
void HAL_GPIO_EXTI_Callback(uint16_t GPIO_Pin)   // callbacks for EXT_INT
{
	//================================================================================
	 if (GPIO_Pin == INT_TOUCH_Pin)  // Touch INT callback
	 {
		 __NOP();
	 }

	 //================================================================================
	 else if (GPIO_Pin == BUT_USR_Pin)  // USER BUT (BLUE HAT) INT callback
	 {
		 myLCD.UsrBut.press = true;

		 myLCD.BL.target_old = myLCD.BL.target;   //save actual brightness
		 myLCD.BL.enable     = true;            //enable brightness change

		 if (!myLCD.BL.dir)  // decreasing brightness
		 {
		   if (myLCD.BL.target >= 50) { myLCD.BL.target -= 50; }
		   else  myLCD.BL.dir = 1;
		 }
		 else  // increasing brightness
		 {
			 if (myLCD.BL.target <= 450) { myLCD.BL.target  += 50; }
			 else  myLCD.BL.dir = 0;
		 }
	 }

}
/**********************************************************************************/

void LVGLTimer(void *argument)
{
  for(;;)
  {
     lv_timer_handler();   // 1 tick ~ 1ms (for 1000Hz RTOS main timer)
	 osDelay(10);          // range 5-10ms, 16 ~ 60FPS
  }
}
/* LVGL tick source */
void LVGLTick(void *argument)
{
  for(;;)
  {
    lv_tick_inc(1);   // range 1-10ms
    osDelay(1);
  }
}

/* USER CODE END 4 */

void StartDefaultTask(void *argument)
{
  /* USER CODE BEGIN 5 */
  /* Infinite loop */
  int press=0;
  static int deftim=0;

  myLCD.BL.enable = true ;            // after main task is started is allowed to start increase backlight PWM

  for(;;)   // run every 1ms
  {
	   // osetreni kmitani user_button
	  if (myLCD.UsrBut.press && (HAL_GPIO_ReadPin(BUT_USR_GPIO_Port, BUT_USR_Pin)))
	  {
		  myLCD.UsrBut.pres_tmr++;
		  if (myLCD.UsrBut.pres_tmr > 100)  // short press - nepouziva se zatim nikde
		  		  myLCD.UsrBut.press_valid = true;
		  if (myLCD.UsrBut.pres_tmr > 2000)   // long press - po jeho stisku se zmeni v RTC zalohovanem
		  {
			  BSP_LED_Toggle(LED_RED);
			  myLCD.UsrBut.long_press_valid = true;
			  if (RTC->BKP0R != 10) RTC->BKP0R = 10;   // po resetu se spusti LV_demo_widget
			  else                  RTC->BKP0R = 0;     // nebo UI_init

			  HAL_NVIC_SystemReset();                   // a vyvolame reset....
		  }
	  }
	  else { myLCD.UsrBut.press = myLCD.UsrBut.press_valid = myLCD.UsrBut.long_press_valid = false; myLCD.UsrBut.pres_tmr = 0; }

	  // pustene tlacitko a citac krateho stisku byl OK / nebo kmitani -> mazeme timer a zaciname od znova
	  if (HAL_GPIO_ReadPin(BUT_USR_GPIO_Port, BUT_USR_Pin) == 0)
	  {
	     myLCD.UsrBut.pres_tmr = 0;
	     if (myLCD.UsrBut.press && (myLCD.UsrBut.press_valid || myLCD.UsrBut.long_press_valid)) {
	        myLCD.UsrBut.press = false; // validni kratky stisk
	    	myLCD.UsrBut.pres_tmr = 0;
	     }

	  }

       // jas dle stisku tlacitka
	  deftim++;
	  LCD_SetBrightness_PT(&myLCD.BL.pt, myLCD.BL.target);

	  if ((deftim % 25) == 0)  // run every 25ms
	  {
		  //print_touch_pos_VT100((uint16_t)TS_StateList.TouchX,(uint16_t)TS_StateList.TouchY);
		  //press = HAL_GPIO_ReadPin(INT_TOUCH_GPIO_Port, INT_TOUCH_Pin);       // if touched => log0
		  //printf("\033[5;0HINT_TOUCH (PG2): %d\n", press); //
		  //printf("\033[7;0HUSR_BUT (PC13): %d\n", HAL_GPIO_ReadPin(BUT_USR_GPIO_Port, BUT_USR_Pin)); //

		  //(press == 0) ? (BSP_LED_On(LED_RED)): (BSP_LED_Off(LED_RED));    // if touched, Red led = on
		  BSP_LED_Toggle(LED_GREEN);
	  }

	  osDelay(1);
   }
  /* USER CODE END 5 */
}

 /* MPU Configuration */

void MPU_Config(void)
{
  MPU_Region_InitTypeDef MPU_InitStruct = {0};

  /* Disables the MPU */
  HAL_MPU_Disable();

  /** Initializes and configures the Region and the memory to be protected
  */
  MPU_InitStruct.Enable = MPU_REGION_ENABLE;
  MPU_InitStruct.Number = MPU_REGION_NUMBER0;
  MPU_InitStruct.BaseAddress = 0x24000000;
  MPU_InitStruct.Size = MPU_REGION_SIZE_512KB;
  MPU_InitStruct.SubRegionDisable = 0x87;
  MPU_InitStruct.TypeExtField = MPU_TEX_LEVEL0;
  MPU_InitStruct.AccessPermission = MPU_REGION_FULL_ACCESS;
  MPU_InitStruct.DisableExec = MPU_INSTRUCTION_ACCESS_DISABLE;
  MPU_InitStruct.IsShareable = MPU_ACCESS_NOT_SHAREABLE;
  MPU_InitStruct.IsCacheable = MPU_ACCESS_CACHEABLE;
  MPU_InitStruct.IsBufferable = MPU_ACCESS_BUFFERABLE;

  HAL_MPU_ConfigRegion(&MPU_InitStruct);

  /** Initializes and configures the Region and the memory to be protected
  */
  MPU_InitStruct.Number = MPU_REGION_NUMBER1;
  MPU_InitStruct.BaseAddress = 0xD0000000;
  MPU_InitStruct.Size = MPU_REGION_SIZE_8MB;
  MPU_InitStruct.SubRegionDisable = 0x0;
  MPU_InitStruct.DisableExec = MPU_INSTRUCTION_ACCESS_ENABLE;
  MPU_InitStruct.IsBufferable = MPU_ACCESS_NOT_BUFFERABLE;

  HAL_MPU_ConfigRegion(&MPU_InitStruct);

  /** Initializes and configures the Region and the memory to be protected
  */
  MPU_InitStruct.Number = MPU_REGION_NUMBER2;
  MPU_InitStruct.BaseAddress = 0x90000000;
  MPU_InitStruct.Size = MPU_REGION_SIZE_128MB;
  MPU_InitStruct.DisableExec = MPU_INSTRUCTION_ACCESS_DISABLE;
  MPU_InitStruct.IsBufferable = MPU_ACCESS_BUFFERABLE;

  HAL_MPU_ConfigRegion(&MPU_InitStruct);
  /* Enables the MPU */
  HAL_MPU_Enable(MPU_PRIVILEGED_DEFAULT);

}

void HAL_TIM_PeriodElapsedCallback(TIM_HandleTypeDef *htim)
{
  if (htim->Instance == TIM6) {
    HAL_IncTick();
  }
}

void Error_Handler(void)
{
  __disable_irq();
  while (1)
  {
  }
}
